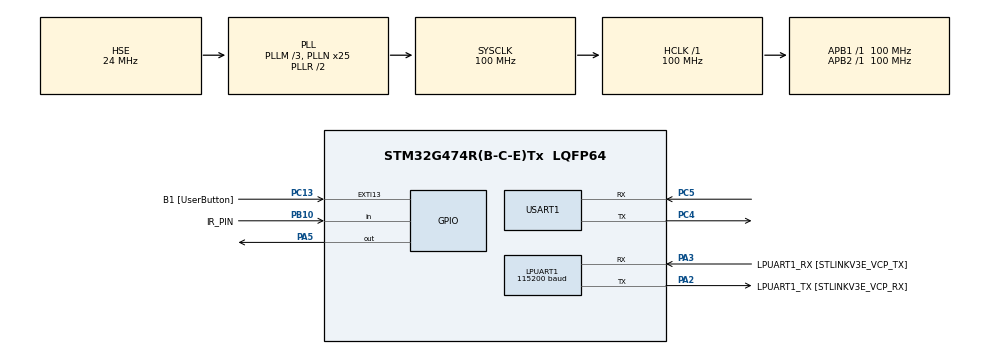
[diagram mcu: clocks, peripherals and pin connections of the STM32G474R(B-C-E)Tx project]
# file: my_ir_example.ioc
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Mcu.Family=STM32G4
RCC.CortexFreq_Value=100000000
PA14.GPIO_Label=T_SWCLK
LPUART1.WordLength=UART_WORDLENGTH_8B
PC5.Mode=Asynchronous
PC13.GPIO_Label=B1 [UserButton]
RCC.SYSCLKSource=RCC_SYSCLKSOURCE_PLLCLK
ProjectManager.StackSize=0x400
RCC.HCLKFreq_Value=100000000
RCC.APB2TimFreq_Value=100000000
RCC.AHBFreq_Value=100000000
NVIC.EXTI15_10_IRQn=true\:0\:0\:false\:false\:true\:true\:true
RCC.HSE_VALUE=24000000
RCC.RTCClockSelection=RCC_RTCCLKSOURCE_LSE
RCC.ADC12Freq_Value=100000000
TIM2.PeriodNoDither=10*1000-1
PC14-OSC32_IN.Mode=LSE-External-Oscillator
PA14.Mode=Serial_Wire
NVIC.TIM2_IRQn=true\:0\:0\:false\:false\:true\:true\:true
VP_SYS_VS_DBSignals.Mode=DisableDeadBatterySignals
Mcu.Package=LQFP64
TIM2.Prescaler=1*1000-1
PA2.GPIO_Label=LPUART1_TX [STLINKV3E_VCP_RX]
RCC.APB1TimFreq_Value=100000000
PC5.Signal=USART1_RX
PF1-OSC_OUT.Mode=HSE-External-Oscillator
PF1-OSC_OUT.Signal=RCC_OSC_OUT
PC4.Mode=Asynchronous
RCC.HSI48_VALUE=48000000
PA3.Signal=LPUART1_RX
PB3.GPIO_Label=T_SWO
RCC.PLLSourceVirtual=RCC_PLLSOURCE_HSE
PC15-OSC32_OUT.Mode=LSE-External-Oscillator
PC13.Signal=GPXTI13
PC4.Signal=USART1_TX
RCC.EXTERNAL_CLOCK_VALUE=12288000
PC14-OSC32_IN.Signal=RCC_OSC32_IN
USART1.VirtualMode-Asynchronous=VM_ASYNC
PA3.Mode=Asynchronous
PA13.Signal=SYS_JTMS-SWDIO
ProjectManager.TargetToolchain=SW4STM32
PB10.GPIO_Label=IR_PIN
RCC.USBFreq_Value=100000000
PC15-OSC32_OUT.Signal=RCC_OSC32_OUT
PF0-OSC_IN.Mode=HSE-External-Oscillator
PB10.Signal=GPIO_Input
PA5.Signal=GPIO_Output
board=NUCLEO-G474RE
RCC.VCOOutputFreq_Value=200000000
RCC.ADC345Freq_Value=100000000
RCC.APB2Freq_Value=100000000
VP_TIM2_VS_ClockSourceINT.Mode=Internal
PA13.Mode=Serial_Wire
Mcu.Name=STM32G474R(B-C-E)Tx
LPUART1.BaudRate=115200
PA13.GPIO_Label=T_SWDIO
PA2.Signal=LPUART1_TX
PB3.Signal=SYS_JTDO-SWO
RCC.SYSCLKFreq_VALUE=100000000
PC13.GPIO_ModeDefaultEXTI=GPIO_MODE_IT_FALLING
PA14.Signal=SYS_JTCK-SWCLK
ProjectManager.HeapSize=0x200
RCC.HSI_VALUE=16000000
NVIC.PriorityGroup=NVIC_PRIORITYGROUP_4
RCC.PLLM=RCC_PLLM_DIV3
RCC.PLLN=25
PA2.Mode=Asynchronous
PF0-OSC_IN.Signal=RCC_OSC_IN
RCC.APB1Freq_Value=100000000
PA3.GPIO_Label=LPUART1_RX [STLINKV3E_VCP_TX]

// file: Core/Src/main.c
/* USER CODE BEGIN Header */
/**
 ******************************************************************************
 * @file           : main.c
 * @brief          : Main program body
 ******************************************************************************
 * @attention
 *
 * <h2><center>&copy; Copyright (c) 2021 STMicroelectronics.
 * All rights reserved.</center></h2>
 *
 * This software component is licensed by ST under BSD 3-Clause license,
 * the "License"; You may not use this file except in compliance with the
 * License. You may obtain a copy of the License at:
 *                        opensource.org/licenses/BSD-3-Clause
 *
 ******************************************************************************
 */
/* USER CODE END Header */
#include "main.h"

/* USER CODE BEGIN Includes */
#include "MySTM32_IR_API.h"
/* USER CODE END Includes */

UART_HandleTypeDef hlpuart1;
UART_HandleTypeDef huart1;

TIM_HandleTypeDef htim2;

void SystemClock_Config(void);
static void MX_GPIO_Init(void);
static void MX_LPUART1_UART_Init(void);
static void MX_TIM2_Init(void);
static void MX_USART1_UART_Init(void);
/* USER CODE BEGIN PFP */
static void UART_TransmitMessage(char *);
/* USER CODE END PFP */

int main(void) {
	/* USER CODE BEGIN 1 */
	char message[16];
	/* USER CODE END 1 */

	/* MCU Configuration--------------------------------------------------------*/

	/* Reset of all peripherals, Initializes the Flash interface and the Systick. */
	HAL_Init();

	/* Configure the system clock */
	SystemClock_Config();

	/* Initialize all configured peripherals */
	MX_GPIO_Init();
	MX_LPUART1_UART_Init();
	MX_TIM2_Init();
	MX_USART1_UART_Init();
	/* USER CODE BEGIN 2 */
	My_IR_Init(&htim2, &huart1, IR_PIN_GPIO_Port, IR_PIN_Pin);
	/* USER CODE END 2 */

	/* Infinite loop */
	/* USER CODE BEGIN WHILE */
	while (1) {

		My_IR_Listening();

		if (My_IR_ReceivedNewCommand) {

			My_IR_GetIrCommandText(message);
			UART_TransmitMessage(message);

			My_IR_ReceivedNewCommand = 0;
		}

//		if (!HAL_UART_Receive(&huart3, caractere, 1, 1000)) {
//
//			strcpy(message, (char *) caractere);
//			UART_TransmitMessage(message);
//		}

//		My_IR_GetIrCommandInHex(timerCount, message);
//		UART_TransmitMessage(message);
//		timerCount++;
//		HAL_Delay(1000);

//		newValue = HAL_GPIO_ReadPin(IR_PIN_GPIO_Port, IR_PIN_Pin) == GPIO_PIN_SET ? 1 : 0;
//
//		if(newValue != oldValue) {
//
//			sprintf(bit, "%i", newValue);
//
//			oldValue = newValue;
//			HAL_UART_Transmit(&huart1, (uint8_t *) bit, strlen(bit), 1000);
//		}

//		timerCount = __HAL_TIM_GET_COUNTER(&htim2);
//		HAL_Delay(50);
//		timerCount = __HAL_TIM_GET_COUNTER(&htim2) - timerCount;
//
//		sprintf(message, "%u us", timerCount);
//		UART_TransmitMessage(message);
//
//		HAL_Delay(50);
		/* USER CODE END WHILE */

	}
}

void SystemClock_Config(void) {
	RCC_OscInitTypeDef RCC_OscInitStruct = { 0 };
	RCC_ClkInitTypeDef RCC_ClkInitStruct = { 0 };
	RCC_PeriphCLKInitTypeDef PeriphClkInit = { 0 };

	/** Configure the main internal regulator output voltage
	 */
	HAL_PWREx_ControlVoltageScaling(PWR_REGULATOR_VOLTAGE_SCALE1);
	/** Initializes the RCC Oscillators according to the specified parameters
	 * in the RCC_OscInitTypeDef structure.
	 */
	RCC_OscInitStruct.OscillatorType = RCC_OSCILLATORTYPE_HSE;
	RCC_OscInitStruct.HSEState = RCC_HSE_ON;
	RCC_OscInitStruct.PLL.PLLState = RCC_PLL_ON;
	RCC_OscInitStruct.PLL.PLLSource = RCC_PLLSOURCE_HSE;
	RCC_OscInitStruct.PLL.PLLM = RCC_PLLM_DIV3;
	RCC_OscInitStruct.PLL.PLLN = 25;
	RCC_OscInitStruct.PLL.PLLP = RCC_PLLP_DIV2;
	RCC_OscInitStruct.PLL.PLLQ = RCC_PLLQ_DIV2;
	RCC_OscInitStruct.PLL.PLLR = RCC_PLLR_DIV2;
	if (HAL_RCC_OscConfig(&RCC_OscInitStruct) != HAL_OK) {
		Error_Handler();
	}
	/** Initializes the CPU, AHB and APB buses clocks
	 */
	RCC_ClkInitStruct.ClockType = RCC_CLOCKTYPE_HCLK | RCC_CLOCKTYPE_SYSCLK | RCC_CLOCKTYPE_PCLK1 | RCC_CLOCKTYPE_PCLK2;
	RCC_ClkInitStruct.SYSCLKSource = RCC_SYSCLKSOURCE_PLLCLK;
	RCC_ClkInitStruct.AHBCLKDivider = RCC_SYSCLK_DIV1;
	RCC_ClkInitStruct.APB1CLKDivider = RCC_HCLK_DIV1;
	RCC_ClkInitStruct.APB2CLKDivider = RCC_HCLK_DIV1;

	if (HAL_RCC_ClockConfig(&RCC_ClkInitStruct, FLASH_LATENCY_2) != HAL_OK) {
		Error_Handler();
	}
	/** Initializes the peripherals clocks
	 */
	PeriphClkInit.PeriphClockSelection = RCC_PERIPHCLK_USART1 | RCC_PERIPHCLK_LPUART1;
	PeriphClkInit.Usart1ClockSelection = RCC_USART1CLKSOURCE_PCLK2;
	PeriphClkInit.Lpuart1ClockSelection = RCC_LPUART1CLKSOURCE_PCLK1;
	if (HAL_RCCEx_PeriphCLKConfig(&PeriphClkInit) != HAL_OK) {
		Error_Handler();
	}
}

static void MX_LPUART1_UART_Init(void) {

	hlpuart1.Instance = LPUART1;
	hlpuart1.Init.BaudRate = 115200;
	hlpuart1.Init.WordLength = UART_WORDLENGTH_8B;
	hlpuart1.Init.StopBits = UART_STOPBITS_1;
	hlpuart1.Init.Parity = UART_PARITY_NONE;
	hlpuart1.Init.Mode = UART_MODE_TX_RX;
	hlpuart1.Init.HwFlowCtl = UART_HWCONTROL_NONE;
	hlpuart1.Init.OneBitSampling = UART_ONE_BIT_SAMPLE_DISABLE;
	hlpuart1.AdvancedInit.AdvFeatureInit = UART_ADVFEATURE_NO_INIT;
	if (HAL_UART_Init(&hlpuart1) != HAL_OK) {
		Error_Handler();
	}
	if (HAL_UARTEx_SetTxFifoThreshold(&hlpuart1, UART_TXFIFO_THRESHOLD_1_8) != HAL_OK) {
		Error_Handler();
	}
	if (HAL_UARTEx_SetRxFifoThreshold(&hlpuart1, UART_RXFIFO_THRESHOLD_1_8) != HAL_OK) {
		Error_Handler();
	}
	if (HAL_UARTEx_DisableFifoMode(&hlpuart1) != HAL_OK) {
		Error_Handler();
	}

}

static void MX_USART1_UART_Init(void) {

	huart1.Instance = USART1;
	huart1.Init.BaudRate = 115200;
	huart1.Init.WordLength = UART_WORDLENGTH_8B;
	huart1.Init.StopBits = UART_STOPBITS_1;
	huart1.Init.Parity = UART_PARITY_NONE;
	huart1.Init.Mode = UART_MODE_TX_RX;
	huart1.Init.HwFlowCtl = UART_HWCONTROL_NONE;
	huart1.Init.OverSampling = UART_OVERSAMPLING_16;
	huart1.Init.OneBitSampling = UART_ONE_BIT_SAMPLE_DISABLE;
	huart1.Init.ClockPrescaler = UART_PRESCALER_DIV1;
	huart1.AdvancedInit.AdvFeatureInit = UART_ADVFEATURE_NO_INIT;
	if (HAL_UART_Init(&huart1) != HAL_OK) {
		Error_Handler();
	}
	if (HAL_UARTEx_SetTxFifoThreshold(&huart1, UART_TXFIFO_THRESHOLD_1_8) != HAL_OK) {
		Error_Handler();
	}
	if (HAL_UARTEx_SetRxFifoThreshold(&huart1, UART_RXFIFO_THRESHOLD_1_8) != HAL_OK) {
		Error_Handler();
	}
	if (HAL_UARTEx_DisableFifoMode(&huart1) != HAL_OK) {
		Error_Handler();
	}

}

static void MX_TIM2_Init(void) {

	TIM_ClockConfigTypeDef sClockSourceConfig = { 0 };
	TIM_MasterConfigTypeDef sMasterConfig = { 0 };

	htim2.Instance = TIM2;
	htim2.Init.Prescaler = 1 * 1000 - 1;
	htim2.Init.CounterMode = TIM_COUNTERMODE_UP;
	htim2.Init.Period = 9999;
	htim2.Init.ClockDivision = TIM_CLOCKDIVISION_DIV1;
	htim2.Init.AutoReloadPreload = TIM_AUTORELOAD_PRELOAD_DISABLE;
	if (HAL_TIM_Base_Init(&htim2) != HAL_OK) {
		Error_Handler();
	}
	sClockSourceConfig.ClockSource = TIM_CLOCKSOURCE_INTERNAL;
	if (HAL_TIM_ConfigClockSource(&htim2, &sClockSourceConfig) != HAL_OK) {
		Error_Handler();
	}
	sMasterConfig.MasterOutputTrigger = TIM_TRGO_RESET;
	sMasterConfig.MasterSlaveMode = TIM_MASTERSLAVEMODE_DISABLE;
	if (HAL_TIMEx_MasterConfigSynchronization(&htim2, &sMasterConfig) != HAL_OK) {
		Error_Handler();
	}

}

static void MX_GPIO_Init(void) {
	GPIO_InitTypeDef GPIO_InitStruct = { 0 };

	/* GPIO Ports Clock Enable */
	__HAL_RCC_GPIOC_CLK_ENABLE()
	;
	__HAL_RCC_GPIOF_CLK_ENABLE()
	;
	__HAL_RCC_GPIOA_CLK_ENABLE()
	;
	__HAL_RCC_GPIOB_CLK_ENABLE()
	;

	/*Configure GPIO pin Output Level */
	HAL_GPIO_WritePin(GPIOA, GPIO_PIN_5, GPIO_PIN_RESET);

	/*Configure GPIO pin : B1_Pin */
	GPIO_InitStruct.Pin = B1_Pin;
	GPIO_InitStruct.Mode = GPIO_MODE_IT_FALLING;
	GPIO_InitStruct.Pull = GPIO_NOPULL;
	HAL_GPIO_Init(B1_GPIO_Port, &GPIO_InitStruct);

	/*Configure GPIO pin : PA5 */
	GPIO_InitStruct.Pin = GPIO_PIN_5;
	GPIO_InitStruct.Mode = GPIO_MODE_OUTPUT_PP;
	GPIO_InitStruct.Pull = GPIO_NOPULL;
	GPIO_InitStruct.Speed = GPIO_SPEED_FREQ_LOW;
	HAL_GPIO_Init(GPIOA, &GPIO_InitStruct);

	/*Configure GPIO pin : IR_PIN_Pin */
	GPIO_InitStruct.Pin = IR_PIN_Pin;
	GPIO_InitStruct.Mode = GPIO_MODE_INPUT;
	GPIO_InitStruct.Pull = GPIO_NOPULL;
	HAL_GPIO_Init(IR_PIN_GPIO_Port, &GPIO_InitStruct);

	/* EXTI interrupt init*/
	HAL_NVIC_SetPriority(EXTI15_10_IRQn, 0, 0);
	HAL_NVIC_EnableIRQ(EXTI15_10_IRQn);

}

/* USER CODE BEGIN 4 */
void UART_TransmitMessage(char * message) {

	char * newLineChar = "\n";
	strcat(message, newLineChar);

	HAL_UART_Transmit(&huart1, (uint8_t *) message, strlen(message), 1000);
}
/* USER CODE END 4 */

void Error_Handler(void) {
}

/************************ (C) COPYRIGHT STMicroelectronics *****END OF FILE****/
